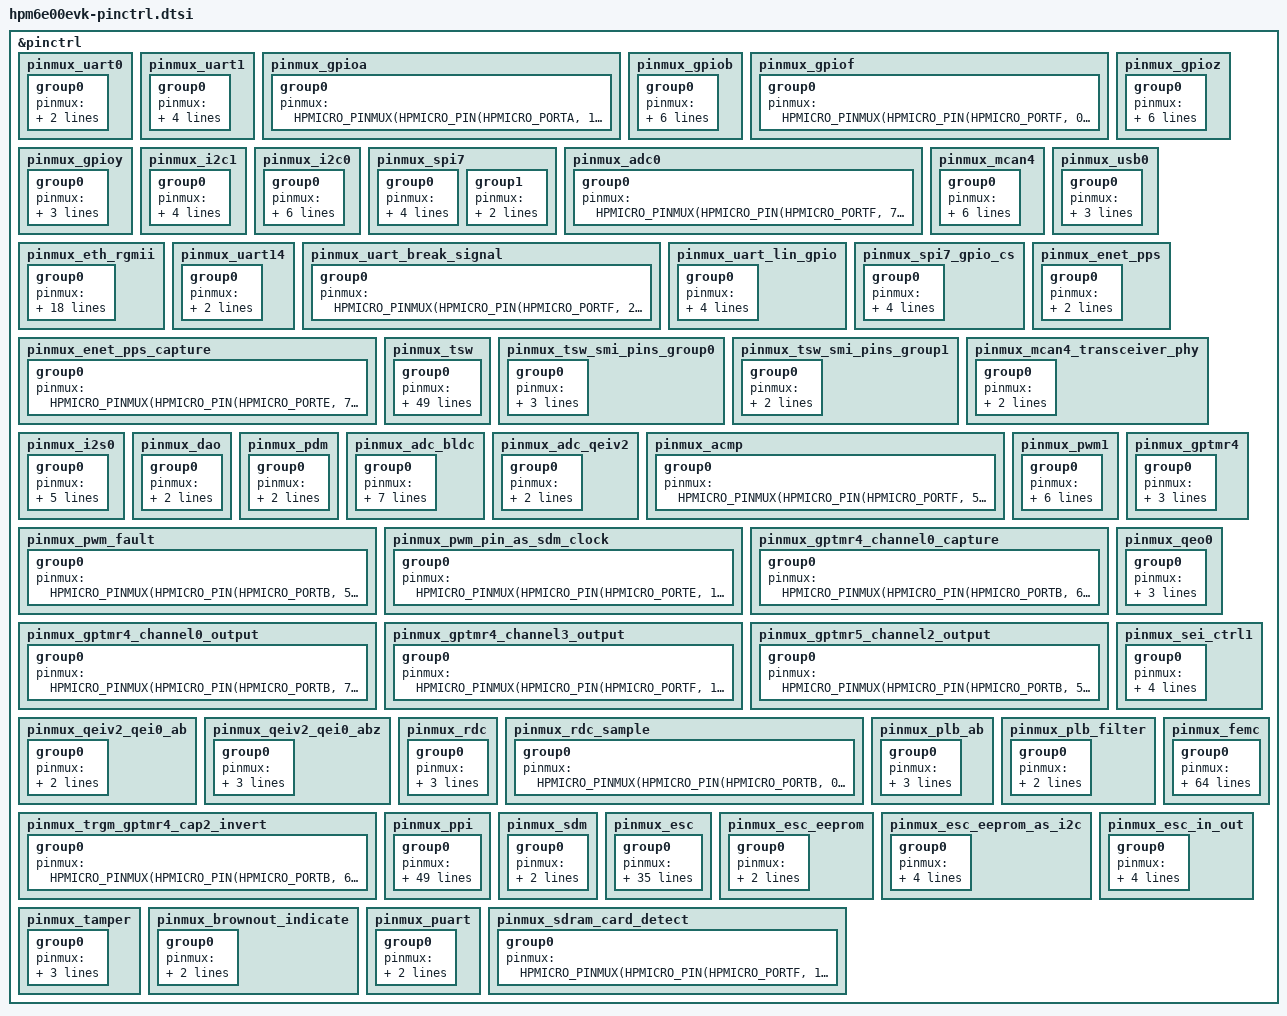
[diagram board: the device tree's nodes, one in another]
/*
* Copyright 2025-2026 HPMicro
* SPDX-License-Identifier: Apache-2.0
*/

#include "dt-bindings/pinctrl/hpmicro-pinctrl-common.h"

&pinctrl {
	pinmux_uart0: pinmux_uart0 {
		group0 {
			pinmux = <HPMICRO_PINMUX(HPMICRO_PIN(HPMICRO_PORTA, 0), IOC_TYPE_IOC, 0, 2)>,
				<HPMICRO_PINMUX(HPMICRO_PIN(HPMICRO_PORTA, 1), IOC_TYPE_IOC, 0, 2)>;
		};
	};

	pinmux_uart1: pinmux_uart1 {
		group0 {
			pinmux = <HPMICRO_PINMUX(HPMICRO_PIN(HPMICRO_PORTY, 7), IOC_TYPE_IOC, 0, 2)>,
				<HPMICRO_PINMUX(HPMICRO_PIN(HPMICRO_PORTY, 7), IOC_TYPE_PIOC, 0, 3)>,
				<HPMICRO_PINMUX(HPMICRO_PIN(HPMICRO_PORTY, 6), IOC_TYPE_IOC, 0, 2)>,
				<HPMICRO_PINMUX(HPMICRO_PIN(HPMICRO_PORTY, 6), IOC_TYPE_PIOC, 0, 3)>;
		};
	};

	pinmux_gpioa: pinmux_gpioa {
		group0 {
			pinmux = <HPMICRO_PINMUX(HPMICRO_PIN(HPMICRO_PORTA, 14), IOC_TYPE_IOC, 0, 0)>;
		};
	};

	pinmux_gpiob: pinmux_gpiob {
		group0 {
			pinmux = <HPMICRO_PINMUX(HPMICRO_PIN(HPMICRO_PORTB, 24), IOC_TYPE_IOC, 0, 0)>,
				<HPMICRO_PINMUX(HPMICRO_PIN(HPMICRO_PORTB, 25), IOC_TYPE_IOC, 0, 0)>;
			bias-pull-up;
			input-enable;
			keeper-capability-disable;
			input-schmitt-enable;
		};
	};

	pinmux_gpiof: pinmux_gpiof {
		group0 {
			pinmux = <HPMICRO_PINMUX(HPMICRO_PIN(HPMICRO_PORTF, 0), IOC_TYPE_IOC, 0, 0)>;
		};
	};

	pinmux_gpioz: pinmux_gpioz {
		group0 {
			pinmux = <HPMICRO_PINMUX(HPMICRO_PIN(HPMICRO_PORTZ, 2), IOC_TYPE_IOC, 0, 0)>,
				<HPMICRO_PINMUX(HPMICRO_PIN(HPMICRO_PORTZ, 2), IOC_TYPE_BIOC, 0, 3)>,
				<HPMICRO_PINMUX(HPMICRO_PIN(HPMICRO_PORTZ, 3), IOC_TYPE_IOC, 0, 0)>,
				<HPMICRO_PINMUX(HPMICRO_PIN(HPMICRO_PORTZ, 3), IOC_TYPE_BIOC, 0, 3)>;
			bias-pull-up;
			input-enable;
		};
	};

	pinmux_gpioy: pinmux_gpioy {
		group0 {
			pinmux = <HPMICRO_PINMUX(HPMICRO_PIN(HPMICRO_PORTY, 5), IOC_TYPE_IOC, 0, 0)>,
				<HPMICRO_PINMUX(HPMICRO_PIN(HPMICRO_PORTY, 5), IOC_TYPE_BIOC, 0, 3)>;
			bias-pull-up;
		};
	};

	pinmux_i2c1: pinmux_i2c1 {
		group0 {
			pinmux = <HPMICRO_PINMUX(HPMICRO_PIN(HPMICRO_PORTF, 12), IOC_TYPE_IOC, 0, 4)>,
				<HPMICRO_PINMUX(HPMICRO_PIN(HPMICRO_PORTF, 13), IOC_TYPE_IOC, 0, 4)>;
			drive-open-drain;
			input-enable;
		};
	};

	pinmux_i2c0: pinmux_i2c0 {
		group0 {
			pinmux = <HPMICRO_PINMUX(HPMICRO_PIN(HPMICRO_PORTY, 2), IOC_TYPE_IOC, 0, 4)>,
				<HPMICRO_PINMUX(HPMICRO_PIN(HPMICRO_PORTY, 2), IOC_TYPE_PIOC, 0, 3)>,
				<HPMICRO_PINMUX(HPMICRO_PIN(HPMICRO_PORTY, 3), IOC_TYPE_IOC, 0, 4)>,
				<HPMICRO_PINMUX(HPMICRO_PIN(HPMICRO_PORTY, 3), IOC_TYPE_PIOC, 0, 3)>;
			drive-open-drain;
			input-enable;
		};
	};

	pinmux_spi7: pinmux_spi7 {
		group0 {
			pinmux = <HPMICRO_PINMUX(HPMICRO_PIN(HPMICRO_PORTF, 26), IOC_TYPE_IOC, 0, 5)>,
				<HPMICRO_PINMUX(HPMICRO_PIN(HPMICRO_PORTF, 28), IOC_TYPE_IOC, 0, 5)>,
				<HPMICRO_PINMUX(HPMICRO_PIN(HPMICRO_PORTF, 29), IOC_TYPE_IOC, 0, 5)>;
			input-enable;
		};

		group1 {
			pinmux = <HPMICRO_PINMUX(HPMICRO_PIN(HPMICRO_PORTF, 27), IOC_TYPE_IOC, 0, 0)>;
			bias-pull-up;
		};
	};

	pinmux_adc0: pinmux_adc0 {
		group0 {
			pinmux = <HPMICRO_PINMUX(HPMICRO_PIN(HPMICRO_PORTF, 7), IOC_TYPE_IOC, 1, 0)>;
		};
	};

	pinmux_mcan4: pinmux_mcan4 {
		group0 {
			pinmux = <HPMICRO_PINMUX(HPMICRO_PIN(HPMICRO_PORTZ, 0), IOC_TYPE_IOC, 0, 7)>,
				<HPMICRO_PINMUX(HPMICRO_PIN(HPMICRO_PORTZ, 1), IOC_TYPE_IOC, 0, 7)>,
				<HPMICRO_PINMUX(HPMICRO_PIN(HPMICRO_PORTZ, 2), IOC_TYPE_IOC, 0, 7)>,
				<HPMICRO_PINMUX(HPMICRO_PIN(HPMICRO_PORTZ, 0), IOC_TYPE_BIOC, 0, 3)>,
				<HPMICRO_PINMUX(HPMICRO_PIN(HPMICRO_PORTZ, 1), IOC_TYPE_BIOC, 0, 3)>,
				<HPMICRO_PINMUX(HPMICRO_PIN(HPMICRO_PORTZ, 2), IOC_TYPE_BIOC, 0, 3)>;
		};
	};

	pinmux_usb0: pinmux_usb0 {
		group0 {
			pinmux = <HPMICRO_PINMUX(HPMICRO_PIN(HPMICRO_PORTF, 19), IOC_TYPE_IOC, 0, 24)>,
				<HPMICRO_PINMUX(HPMICRO_PIN(HPMICRO_PORTF, 22), IOC_TYPE_IOC, 0, 24)>,
				<HPMICRO_PINMUX(HPMICRO_PIN(HPMICRO_PORTF, 23), IOC_TYPE_IOC, 0, 24)>;
		};
	};

	pinmux_eth_rgmii: pinmux_eth_rgmii {
		group0 {
			pinmux = <HPMICRO_PINMUX(HPMICRO_PIN(HPMICRO_PORTF, 1), IOC_TYPE_IOC, 0, 18)>,
				<HPMICRO_PINMUX(HPMICRO_PIN(HPMICRO_PORTF, 0), IOC_TYPE_IOC, 0, 18)>,
				<HPMICRO_PINMUX(HPMICRO_PIN(HPMICRO_PORTE, 20), IOC_TYPE_IOC, 0, 18)>,
				<HPMICRO_PINMUX(HPMICRO_PIN(HPMICRO_PORTE, 21), IOC_TYPE_IOC, 0, 18)>,
				<HPMICRO_PINMUX(HPMICRO_PIN(HPMICRO_PORTE, 22), IOC_TYPE_IOC, 0, 18)>,
				<HPMICRO_PINMUX(HPMICRO_PIN(HPMICRO_PORTE, 23), IOC_TYPE_IOC, 0, 18)>,
				<HPMICRO_PINMUX(HPMICRO_PIN(HPMICRO_PORTE, 24), IOC_TYPE_IOC, 0, 18)>,
				<HPMICRO_PINMUX(HPMICRO_PIN(HPMICRO_PORTE, 25), IOC_TYPE_IOC, 0, 18)>,
				<HPMICRO_PINMUX(HPMICRO_PIN(HPMICRO_PORTE, 26), IOC_TYPE_IOC, 0, 18)>,
				<HPMICRO_PINMUX(HPMICRO_PIN(HPMICRO_PORTE, 27), IOC_TYPE_IOC, 0, 18)>,
				<HPMICRO_PINMUX(HPMICRO_PIN(HPMICRO_PORTE, 28), IOC_TYPE_IOC, 0, 18)>,
				<HPMICRO_PINMUX(HPMICRO_PIN(HPMICRO_PORTE, 29), IOC_TYPE_IOC, 0, 18)>,
				<HPMICRO_PINMUX(HPMICRO_PIN(HPMICRO_PORTE, 30), IOC_TYPE_IOC, 0, 18)>,
				<HPMICRO_PINMUX(HPMICRO_PIN(HPMICRO_PORTE, 31), IOC_TYPE_IOC, 0, 18)>;
			input-schmitt-enable;
			slew-rate = "fast";
			slew-pd = "100M";
			drive-strength = "r011";
		};
	};

	pinmux_uart14: pinmux_uart14 {
		group0 {
			pinmux = <HPMICRO_PINMUX(HPMICRO_PIN(HPMICRO_PORTF, 24), IOC_TYPE_IOC, 0, 2)>,
				<HPMICRO_PINMUX(HPMICRO_PIN(HPMICRO_PORTF, 25), IOC_TYPE_IOC, 0, 2)>;
		};
	};

	pinmux_uart_break_signal: pinmux_uart_break_signal {
		group0 {
			pinmux = <HPMICRO_PINMUX(HPMICRO_PIN(HPMICRO_PORTF, 27), IOC_TYPE_IOC, 0, 0)>;
		};
	};

	pinmux_uart_lin_gpio: pinmux_uart_lin_gpio {
		group0 {
			pinmux = <HPMICRO_PINMUX(HPMICRO_PIN(HPMICRO_PORTY, 7), IOC_TYPE_IOC, 0, 0)>,
				<HPMICRO_PINMUX(HPMICRO_PIN(HPMICRO_PORTY, 7), IOC_TYPE_PIOC, 0, 3)>,
				<HPMICRO_PINMUX(HPMICRO_PIN(HPMICRO_PORTY, 6), IOC_TYPE_IOC, 0, 0)>,
				<HPMICRO_PINMUX(HPMICRO_PIN(HPMICRO_PORTY, 6), IOC_TYPE_PIOC, 0, 3)>;
		};
	};

	pinmux_spi7_gpio_cs: pinmux_spi7_gpio_cs {
		group0 {
			pinmux = <HPMICRO_PINMUX(HPMICRO_PIN(HPMICRO_PORTF, 27), IOC_TYPE_IOC, 0, 0)>,
				<HPMICRO_PINMUX(HPMICRO_PIN(HPMICRO_PORTF, 26), IOC_TYPE_IOC, 0, 5)>,
				<HPMICRO_PINMUX(HPMICRO_PIN(HPMICRO_PORTF, 28), IOC_TYPE_IOC, 0, 5)>,
				<HPMICRO_PINMUX(HPMICRO_PIN(HPMICRO_PORTF, 29), IOC_TYPE_IOC, 0, 5)>;
		};
	};

	pinmux_enet_pps: pinmux_enet_pps {
		group0 {
			pinmux = <HPMICRO_PINMUX(HPMICRO_PIN(HPMICRO_PORTE, 6), IOC_TYPE_IOC, 0, 25)>,
				<HPMICRO_PINMUX(HPMICRO_PIN(HPMICRO_PORTF, 20), IOC_TYPE_IOC, 0, 25)>;
		};
	};

	pinmux_enet_pps_capture: pinmux_enet_pps_capture {
		group0 {
			pinmux = <HPMICRO_PINMUX(HPMICRO_PIN(HPMICRO_PORTE, 7), IOC_TYPE_IOC, 0, 25)>;
		};
	};

	pinmux_tsw: pinmux_tsw {
		group0 {
			pinmux = <HPMICRO_PINMUX(HPMICRO_PIN(HPMICRO_PORTA, 16), IOC_TYPE_IOC, 0, 10)>,
				<HPMICRO_PINMUX(HPMICRO_PIN(HPMICRO_PORTA, 21), IOC_TYPE_IOC, 0, 10)>,
				<HPMICRO_PINMUX(HPMICRO_PIN(HPMICRO_PORTA, 17), IOC_TYPE_IOC, 0, 10)>,
				<HPMICRO_PINMUX(HPMICRO_PIN(HPMICRO_PORTA, 18), IOC_TYPE_IOC, 0, 10)>,
				<HPMICRO_PINMUX(HPMICRO_PIN(HPMICRO_PORTA, 19), IOC_TYPE_IOC, 0, 10)>,
				<HPMICRO_PINMUX(HPMICRO_PIN(HPMICRO_PORTA, 20), IOC_TYPE_IOC, 0, 10)>,
				<HPMICRO_PINMUX(HPMICRO_PIN(HPMICRO_PORTA, 29), IOC_TYPE_IOC, 0, 10)>,
				<HPMICRO_PINMUX(HPMICRO_PIN(HPMICRO_PORTA, 24), IOC_TYPE_IOC, 0, 10)>,
				<HPMICRO_PINMUX(HPMICRO_PIN(HPMICRO_PORTA, 25), IOC_TYPE_IOC, 0, 10)>,
				<HPMICRO_PINMUX(HPMICRO_PIN(HPMICRO_PORTA, 26), IOC_TYPE_IOC, 0, 10)>,
				<HPMICRO_PINMUX(HPMICRO_PIN(HPMICRO_PORTA, 27), IOC_TYPE_IOC, 0, 10)>,
				<HPMICRO_PINMUX(HPMICRO_PIN(HPMICRO_PORTA, 28), IOC_TYPE_IOC, 0, 10)>,
				<HPMICRO_PINMUX(HPMICRO_PIN(HPMICRO_PORTA, 23), IOC_TYPE_IOC, 0, 10)>,
				<HPMICRO_PINMUX(HPMICRO_PIN(HPMICRO_PORTA, 30), IOC_TYPE_IOC, 0, 10)>,
				<HPMICRO_PINMUX(HPMICRO_PIN(HPMICRO_PORTA, 31), IOC_TYPE_IOC, 0, 10)>,
				<HPMICRO_PINMUX(HPMICRO_PIN(HPMICRO_PORTB, 12), IOC_TYPE_IOC, 0, 10)>,
				<HPMICRO_PINMUX(HPMICRO_PIN(HPMICRO_PORTB, 17), IOC_TYPE_IOC, 0, 10)>,
				<HPMICRO_PINMUX(HPMICRO_PIN(HPMICRO_PORTB, 13), IOC_TYPE_IOC, 0, 10)>,
				<HPMICRO_PINMUX(HPMICRO_PIN(HPMICRO_PORTB, 14), IOC_TYPE_IOC, 0, 10)>,
				<HPMICRO_PINMUX(HPMICRO_PIN(HPMICRO_PORTB, 15), IOC_TYPE_IOC, 0, 10)>,
				<HPMICRO_PINMUX(HPMICRO_PIN(HPMICRO_PORTB, 16), IOC_TYPE_IOC, 0, 10)>,
				<HPMICRO_PINMUX(HPMICRO_PIN(HPMICRO_PORTB, 23), IOC_TYPE_IOC, 0, 10)>,
				<HPMICRO_PINMUX(HPMICRO_PIN(HPMICRO_PORTB, 18), IOC_TYPE_IOC, 0, 10)>,
				<HPMICRO_PINMUX(HPMICRO_PIN(HPMICRO_PORTB, 19), IOC_TYPE_IOC, 0, 10)>,
				<HPMICRO_PINMUX(HPMICRO_PIN(HPMICRO_PORTB, 20), IOC_TYPE_IOC, 0, 10)>,
				<HPMICRO_PINMUX(HPMICRO_PIN(HPMICRO_PORTB, 21), IOC_TYPE_IOC, 0, 10)>,
				<HPMICRO_PINMUX(HPMICRO_PIN(HPMICRO_PORTB, 22), IOC_TYPE_IOC, 0, 10)>,
				<HPMICRO_PINMUX(HPMICRO_PIN(HPMICRO_PORTA, 22), IOC_TYPE_IOC, 0, 10)>,
				<HPMICRO_PINMUX(HPMICRO_PIN(HPMICRO_PORTE, 3), IOC_TYPE_IOC, 0, 10)>,
				<HPMICRO_PINMUX(HPMICRO_PIN(HPMICRO_PORTE, 4), IOC_TYPE_IOC, 0, 10)>,
				<HPMICRO_PINMUX(HPMICRO_PIN(HPMICRO_PORTA, 10), IOC_TYPE_IOC, 0, 0)>,
				<HPMICRO_PINMUX(HPMICRO_PIN(HPMICRO_PORTA, 9), IOC_TYPE_IOC, 0, 11)>,
				<HPMICRO_PINMUX(HPMICRO_PIN(HPMICRO_PORTE, 20), IOC_TYPE_IOC, 0, 10)>,
				<HPMICRO_PINMUX(HPMICRO_PIN(HPMICRO_PORTE, 25), IOC_TYPE_IOC, 0, 10)>,
				<HPMICRO_PINMUX(HPMICRO_PIN(HPMICRO_PORTE, 21), IOC_TYPE_IOC, 0, 10)>,
				<HPMICRO_PINMUX(HPMICRO_PIN(HPMICRO_PORTE, 22), IOC_TYPE_IOC, 0, 10)>,
				<HPMICRO_PINMUX(HPMICRO_PIN(HPMICRO_PORTE, 23), IOC_TYPE_IOC, 0, 10)>,
				<HPMICRO_PINMUX(HPMICRO_PIN(HPMICRO_PORTE, 24), IOC_TYPE_IOC, 0, 10)>,
				<HPMICRO_PINMUX(HPMICRO_PIN(HPMICRO_PORTE, 31), IOC_TYPE_IOC, 0, 10)>,
				<HPMICRO_PINMUX(HPMICRO_PIN(HPMICRO_PORTE, 26), IOC_TYPE_IOC, 0, 10)>,
				<HPMICRO_PINMUX(HPMICRO_PIN(HPMICRO_PORTE, 27), IOC_TYPE_IOC, 0, 10)>,
				<HPMICRO_PINMUX(HPMICRO_PIN(HPMICRO_PORTE, 28), IOC_TYPE_IOC, 0, 10)>,
				<HPMICRO_PINMUX(HPMICRO_PIN(HPMICRO_PORTE, 29), IOC_TYPE_IOC, 0, 10)>,
				<HPMICRO_PINMUX(HPMICRO_PIN(HPMICRO_PORTE, 30), IOC_TYPE_IOC, 0, 10)>,
				<HPMICRO_PINMUX(HPMICRO_PIN(HPMICRO_PORTF, 0), IOC_TYPE_IOC, 0, 10)>,
				<HPMICRO_PINMUX(HPMICRO_PIN(HPMICRO_PORTF, 1), IOC_TYPE_IOC, 0, 10)>,
				<HPMICRO_PINMUX(HPMICRO_PIN(HPMICRO_PORTB, 9), IOC_TYPE_IOC, 0, 0)>,
				<HPMICRO_PINMUX(HPMICRO_PIN(HPMICRO_PORTA, 14), IOC_TYPE_IOC, 0, 0)>,
				<HPMICRO_PINMUX(HPMICRO_PIN(HPMICRO_PORTB, 25), IOC_TYPE_IOC, 0, 26)>;
		};
	};

	pinmux_tsw_smi_pins_group0: pinmux_tsw_smi_pins_group0 {
		group0 {
			pinmux = <HPMICRO_PINMUX(HPMICRO_PIN(HPMICRO_PORTA, 30), IOC_TYPE_IOC, 0, 18)>,
				<HPMICRO_PINMUX(HPMICRO_PIN(HPMICRO_PORTA, 31), IOC_TYPE_IOC, 0, 18)>,
				<HPMICRO_PINMUX(HPMICRO_PIN(HPMICRO_PORTA, 9), IOC_TYPE_IOC, 0, 11)>;
		};
	};

	pinmux_tsw_smi_pins_group1: pinmux_tsw_smi_pins_group1 {
		group0 {
			pinmux = <HPMICRO_PINMUX(HPMICRO_PIN(HPMICRO_PORTF, 1), IOC_TYPE_IOC, 0, 18)>,
				<HPMICRO_PINMUX(HPMICRO_PIN(HPMICRO_PORTF, 0), IOC_TYPE_IOC, 0, 18)>;
		};
	};

	pinmux_mcan4_transceiver_phy: pinmux_mcan4_transceiver_phy {
		group0 {
			pinmux = <HPMICRO_PINMUX(HPMICRO_PIN(HPMICRO_PORTZ, 2), IOC_TYPE_IOC, 0, 0)>,
				<HPMICRO_PINMUX(HPMICRO_PIN(HPMICRO_PORTZ, 2), IOC_TYPE_BIOC, 0, 3)>;
		};
	};

	pinmux_i2s0: pinmux_i2s0 {
		group0 {
			pinmux = <HPMICRO_PINMUX(HPMICRO_PIN(HPMICRO_PORTB, 11), IOC_TYPE_IOC, 0, 8)>,
				<HPMICRO_PINMUX(HPMICRO_PIN(HPMICRO_PORTB, 1), IOC_TYPE_IOC, 0, 8)>,
				<HPMICRO_PINMUX(HPMICRO_PIN(HPMICRO_PORTB, 10), IOC_TYPE_IOC, 0, 8)>,
				<HPMICRO_PINMUX(HPMICRO_PIN(HPMICRO_PORTB, 0), IOC_TYPE_IOC, 0, 8)>,
				<HPMICRO_PINMUX(HPMICRO_PIN(HPMICRO_PORTB, 8), IOC_TYPE_IOC, 0, 8)>;
		};
	};

	pinmux_dao: pinmux_dao {
		group0 {
			pinmux = <HPMICRO_PINMUX(HPMICRO_PIN(HPMICRO_PORTF, 4), IOC_TYPE_IOC, 0, 9)>,
				<HPMICRO_PINMUX(HPMICRO_PIN(HPMICRO_PORTF, 3), IOC_TYPE_IOC, 0, 9)>;
		};
	};

	pinmux_pdm: pinmux_pdm {
		group0 {
			pinmux = <HPMICRO_PINMUX(HPMICRO_PIN(HPMICRO_PORTB, 2), IOC_TYPE_IOC, 0, 9)>,
				<HPMICRO_PINMUX(HPMICRO_PIN(HPMICRO_PORTB, 3), IOC_TYPE_IOC, 0, 9)>;
		};
	};

	pinmux_adc_bldc: pinmux_adc_bldc {
		group0 {
			pinmux = <HPMICRO_PINMUX(HPMICRO_PIN(HPMICRO_PORTF, 6), IOC_TYPE_IOC, 1, 0)>,
				<HPMICRO_PINMUX(HPMICRO_PIN(HPMICRO_PORTF, 8), IOC_TYPE_IOC, 1, 0)>,
				<HPMICRO_PINMUX(HPMICRO_PIN(HPMICRO_PORTF, 19), IOC_TYPE_IOC, 1, 0)>,
				<HPMICRO_PINMUX(HPMICRO_PIN(HPMICRO_PORTF, 10), IOC_TYPE_IOC, 1, 0)>,
				<HPMICRO_PINMUX(HPMICRO_PIN(HPMICRO_PORTF, 7), IOC_TYPE_IOC, 1, 0)>,
				<HPMICRO_PINMUX(HPMICRO_PIN(HPMICRO_PORTF, 27), IOC_TYPE_IOC, 1, 0)>,
				<HPMICRO_PINMUX(HPMICRO_PIN(HPMICRO_PORTF, 20), IOC_TYPE_IOC, 1, 0)>;
		};
	};

	pinmux_adc_qeiv2: pinmux_adc_qeiv2 {
		group0 {
			pinmux = <HPMICRO_PINMUX(HPMICRO_PIN(HPMICRO_PORTF, 19), IOC_TYPE_IOC, 1, 0)>,
				<HPMICRO_PINMUX(HPMICRO_PIN(HPMICRO_PORTF, 6), IOC_TYPE_IOC, 1, 0)>;
		};
	};

	pinmux_acmp: pinmux_acmp {
		group0 {
			pinmux = <HPMICRO_PINMUX(HPMICRO_PIN(HPMICRO_PORTF, 5), IOC_TYPE_IOC, 1, 0)>;
		};
	};

	pinmux_pwm1: pinmux_pwm1 {
		group0 {
			pinmux = <HPMICRO_PINMUX(HPMICRO_PIN(HPMICRO_PORTE, 8), IOC_TYPE_IOC, 0, 16)>,
				<HPMICRO_PINMUX(HPMICRO_PIN(HPMICRO_PORTE, 9), IOC_TYPE_IOC, 0, 16)>,
				<HPMICRO_PINMUX(HPMICRO_PIN(HPMICRO_PORTE, 10), IOC_TYPE_IOC, 0, 16)>,
				<HPMICRO_PINMUX(HPMICRO_PIN(HPMICRO_PORTE, 11), IOC_TYPE_IOC, 0, 16)>,
				<HPMICRO_PINMUX(HPMICRO_PIN(HPMICRO_PORTE, 12), IOC_TYPE_IOC, 0, 16)>,
				<HPMICRO_PINMUX(HPMICRO_PIN(HPMICRO_PORTE, 13), IOC_TYPE_IOC, 0, 16)>;
		};
	};

	pinmux_pwm_fault: pinmux_pwm_fault {
		group0 {
			pinmux = <HPMICRO_PINMUX(HPMICRO_PIN(HPMICRO_PORTB, 5), IOC_TYPE_IOC, 0, 17)>;
		};
	};

	pinmux_pwm_pin_as_sdm_clock: pinmux_pwm_pin_as_sdm_clock {
		group0 {
			pinmux = <HPMICRO_PINMUX(HPMICRO_PIN(HPMICRO_PORTE, 19), IOC_TYPE_IOC, 0, 16)>;
		};
	};

	pinmux_gptmr4: pinmux_gptmr4 {
		group0 {
			pinmux = <HPMICRO_PINMUX(HPMICRO_PIN(HPMICRO_PORTB, 6), IOC_TYPE_IOC, 0, 1)>,
				<HPMICRO_PINMUX(HPMICRO_PIN(HPMICRO_PORTB, 7), IOC_TYPE_IOC, 0, 1)>,
				<HPMICRO_PINMUX(HPMICRO_PIN(HPMICRO_PORTF, 15), IOC_TYPE_IOC, 0, 1)>;
		};
	};

	pinmux_gptmr4_channel0_capture: pinmux_gptmr4_channel0_capture {
		group0 {
			pinmux = <HPMICRO_PINMUX(HPMICRO_PIN(HPMICRO_PORTB, 6), IOC_TYPE_IOC, 0, 1)>;
		};
	};

	pinmux_gptmr4_channel0_output: pinmux_gptmr4_channel0_output {
		group0 {
			pinmux = <HPMICRO_PINMUX(HPMICRO_PIN(HPMICRO_PORTB, 7), IOC_TYPE_IOC, 0, 1)>;
		};
	};

	pinmux_gptmr4_channel3_output: pinmux_gptmr4_channel3_output {
		group0 {
			pinmux = <HPMICRO_PINMUX(HPMICRO_PIN(HPMICRO_PORTF, 15), IOC_TYPE_IOC, 0, 1)>;
		};
	};

	pinmux_gptmr5_channel2_output: pinmux_gptmr5_channel2_output {
		group0 {
			pinmux = <HPMICRO_PINMUX(HPMICRO_PIN(HPMICRO_PORTB, 5), IOC_TYPE_IOC, 0, 1)>;
		};
	};

	pinmux_qeo0: pinmux_qeo0 {
		group0 {
			pinmux = <HPMICRO_PINMUX(HPMICRO_PIN(HPMICRO_PORTE, 7), IOC_TYPE_IOC, 0, 21)>,
				<HPMICRO_PINMUX(HPMICRO_PIN(HPMICRO_PORTE, 6), IOC_TYPE_IOC, 0, 21)>,
				<HPMICRO_PINMUX(HPMICRO_PIN(HPMICRO_PORTE, 5), IOC_TYPE_IOC, 0, 21)>;
		};
	};

	pinmux_qeiv2_qei0_ab: pinmux_qeiv2_qei0_ab {
		group0 {
			pinmux = <HPMICRO_PINMUX(HPMICRO_PIN(HPMICRO_PORTB, 7), IOC_TYPE_IOC, 0, 20)>,
				<HPMICRO_PINMUX(HPMICRO_PIN(HPMICRO_PORTB, 6), IOC_TYPE_IOC, 0, 20)>;
		};
	};

	pinmux_qeiv2_qei0_abz: pinmux_qeiv2_qei0_abz {
		group0 {
			pinmux = <HPMICRO_PINMUX(HPMICRO_PIN(HPMICRO_PORTB, 7), IOC_TYPE_IOC, 0, 20)>,
				<HPMICRO_PINMUX(HPMICRO_PIN(HPMICRO_PORTB, 6), IOC_TYPE_IOC, 0, 20)>,
				<HPMICRO_PINMUX(HPMICRO_PIN(HPMICRO_PORTB, 5), IOC_TYPE_IOC, 0, 20)>;
		};
	};

	pinmux_sei_ctrl1: pinmux_sei_ctrl1 {
		group0 {
			pinmux = <HPMICRO_PINMUX(HPMICRO_PIN(HPMICRO_PORTE, 18), IOC_TYPE_IOC, 0, 22)>,
				<HPMICRO_PINMUX(HPMICRO_PIN(HPMICRO_PORTE, 19), IOC_TYPE_IOC, 0, 22)>,
				<HPMICRO_PINMUX(HPMICRO_PIN(HPMICRO_PORTE, 16), IOC_TYPE_IOC, 0, 22)>,
				<HPMICRO_PINMUX(HPMICRO_PIN(HPMICRO_PORTE, 17), IOC_TYPE_IOC, 0, 22)>;
		};
	};

	pinmux_rdc: pinmux_rdc {
		group0 {
			pinmux = <HPMICRO_PINMUX(HPMICRO_PIN(HPMICRO_PORTF, 6), IOC_TYPE_IOC, 1, 0)>,
				<HPMICRO_PINMUX(HPMICRO_PIN(HPMICRO_PORTF, 8), IOC_TYPE_IOC, 1, 0)>,
				<HPMICRO_PINMUX(HPMICRO_PIN(HPMICRO_PORTE, 8), IOC_TYPE_IOC, 0, 20)>;
		};
	};

	pinmux_rdc_sample: pinmux_rdc_sample {
		group0 {
			pinmux = <HPMICRO_PINMUX(HPMICRO_PIN(HPMICRO_PORTB, 0), IOC_TYPE_IOC, 0, 17)>;
		};
	};

	pinmux_plb_ab: pinmux_plb_ab {
		group0 {
			pinmux = <HPMICRO_PINMUX(HPMICRO_PIN(HPMICRO_PORTB, 7), IOC_TYPE_IOC, 0, 17)>,
				<HPMICRO_PINMUX(HPMICRO_PIN(HPMICRO_PORTB, 6), IOC_TYPE_IOC, 0, 17)>,
				<HPMICRO_PINMUX(HPMICRO_PIN(HPMICRO_PORTB, 5), IOC_TYPE_IOC, 0, 17)>;
		};
	};

	pinmux_plb_filter: pinmux_plb_filter {
		group0 {
			pinmux = <HPMICRO_PINMUX(HPMICRO_PIN(HPMICRO_PORTE, 10), IOC_TYPE_IOC, 0, 17)>,
				<HPMICRO_PINMUX(HPMICRO_PIN(HPMICRO_PORTE, 12), IOC_TYPE_IOC, 0, 17)>;
		};
	};

	pinmux_trgm_gptmr4_cap2_invert: pinmux_trgm_gptmr4_cap2_invert {
		group0 {
			pinmux = <HPMICRO_PINMUX(HPMICRO_PIN(HPMICRO_PORTB, 6), IOC_TYPE_IOC, 0, 17)>;
		};
	};

	pinmux_femc: pinmux_femc {
		group0 {
			pinmux = <HPMICRO_PINMUX(HPMICRO_PIN(HPMICRO_PORTD, 2), IOC_TYPE_IOC, 0, 12)>,
				<HPMICRO_PINMUX(HPMICRO_PIN(HPMICRO_PORTD, 3), IOC_TYPE_IOC, 0, 12)>,
				<HPMICRO_PINMUX(HPMICRO_PIN(HPMICRO_PORTD, 0), IOC_TYPE_IOC, 0, 12)>,
				<HPMICRO_PINMUX(HPMICRO_PIN(HPMICRO_PORTD, 1), IOC_TYPE_IOC, 0, 12)>,
				<HPMICRO_PINMUX(HPMICRO_PIN(HPMICRO_PORTC, 18), IOC_TYPE_IOC, 0, 12)>,
				<HPMICRO_PINMUX(HPMICRO_PIN(HPMICRO_PORTC, 19), IOC_TYPE_IOC, 0, 12)>,
				<HPMICRO_PINMUX(HPMICRO_PIN(HPMICRO_PORTC, 20), IOC_TYPE_IOC, 0, 12)>,
				<HPMICRO_PINMUX(HPMICRO_PIN(HPMICRO_PORTC, 21), IOC_TYPE_IOC, 0, 12)>,
				<HPMICRO_PINMUX(HPMICRO_PIN(HPMICRO_PORTC, 23), IOC_TYPE_IOC, 0, 12)>,
				<HPMICRO_PINMUX(HPMICRO_PIN(HPMICRO_PORTC, 24), IOC_TYPE_IOC, 0, 12)>,
				<HPMICRO_PINMUX(HPMICRO_PIN(HPMICRO_PORTD, 4), IOC_TYPE_IOC, 0, 12)>,
				<HPMICRO_PINMUX(HPMICRO_PIN(HPMICRO_PORTC, 25), IOC_TYPE_IOC, 0, 12)>,
				<HPMICRO_PINMUX(HPMICRO_PIN(HPMICRO_PORTC, 26), IOC_TYPE_IOC, 0, 12)>,
				<HPMICRO_PINMUX(HPMICRO_PIN(HPMICRO_PORTD, 31), IOC_TYPE_IOC, 0, 12)>,
				<HPMICRO_PINMUX(HPMICRO_PIN(HPMICRO_PORTD, 30), IOC_TYPE_IOC, 0, 12)>,
				<HPMICRO_PINMUX(HPMICRO_PIN(HPMICRO_PORTD, 29), IOC_TYPE_IOC, 0, 12)>,
				<HPMICRO_PINMUX(HPMICRO_PIN(HPMICRO_PORTD, 28), IOC_TYPE_IOC, 0, 12)>,
				<HPMICRO_PINMUX(HPMICRO_PIN(HPMICRO_PORTD, 27), IOC_TYPE_IOC, 0, 12)>,
				<HPMICRO_PINMUX(HPMICRO_PIN(HPMICRO_PORTD, 26), IOC_TYPE_IOC, 0, 12)>,
				<HPMICRO_PINMUX(HPMICRO_PIN(HPMICRO_PORTD, 24), IOC_TYPE_IOC, 0, 12)>,
				<HPMICRO_PINMUX(HPMICRO_PIN(HPMICRO_PORTD, 25), IOC_TYPE_IOC, 0, 12)>,
				<HPMICRO_PINMUX(HPMICRO_PIN(HPMICRO_PORTD, 14), IOC_TYPE_IOC, 0, 12)>,
				<HPMICRO_PINMUX(HPMICRO_PIN(HPMICRO_PORTD, 17), IOC_TYPE_IOC, 0, 12)>,
				<HPMICRO_PINMUX(HPMICRO_PIN(HPMICRO_PORTD, 16), IOC_TYPE_IOC, 0, 12)>,
				<HPMICRO_PINMUX(HPMICRO_PIN(HPMICRO_PORTD, 19), IOC_TYPE_IOC, 0, 12)>,
				<HPMICRO_PINMUX(HPMICRO_PIN(HPMICRO_PORTD, 18), IOC_TYPE_IOC, 0, 12)>,
				<HPMICRO_PINMUX(HPMICRO_PIN(HPMICRO_PORTD, 21), IOC_TYPE_IOC, 0, 12)>,
				<HPMICRO_PINMUX(HPMICRO_PIN(HPMICRO_PORTD, 20), IOC_TYPE_IOC, 0, 12)>,
				<HPMICRO_PINMUX(HPMICRO_PIN(HPMICRO_PORTD, 22), IOC_TYPE_IOC, 0, 12)>,
				<HPMICRO_PINMUX(HPMICRO_PIN(HPMICRO_PORTC, 16), IOC_TYPE_IOC, 0, 12)>,
				<HPMICRO_PINMUX(HPMICRO_PIN(HPMICRO_PORTC, 17), IOC_TYPE_IOC, 0, 12)>,
				<HPMICRO_PINMUX(HPMICRO_PIN(HPMICRO_PORTC, 13), IOC_TYPE_IOC, 0, 12)>,
				<HPMICRO_PINMUX(HPMICRO_PIN(HPMICRO_PORTC, 14), IOC_TYPE_IOC, 0, 12)>,
				<HPMICRO_PINMUX(HPMICRO_PIN(HPMICRO_PORTC, 10), IOC_TYPE_IOC, 0, 12)>,
				<HPMICRO_PINMUX(HPMICRO_PIN(HPMICRO_PORTC, 11), IOC_TYPE_IOC, 0, 12)>,
				<HPMICRO_PINMUX(HPMICRO_PIN(HPMICRO_PORTC, 2), IOC_TYPE_IOC, 0, 12)>,
				<HPMICRO_PINMUX(HPMICRO_PIN(HPMICRO_PORTC, 9), IOC_TYPE_IOC, 0, 12)>,
				<HPMICRO_PINMUX(HPMICRO_PIN(HPMICRO_PORTC, 0), IOC_TYPE_IOC, 0, 12)>,
				<HPMICRO_PINMUX(HPMICRO_PIN(HPMICRO_PORTC, 1), IOC_TYPE_IOC, 0, 12)>,
				<HPMICRO_PINMUX(HPMICRO_PIN(HPMICRO_PORTC, 3), IOC_TYPE_IOC, 0, 12)>,
				<HPMICRO_PINMUX(HPMICRO_PIN(HPMICRO_PORTC, 4), IOC_TYPE_IOC, 0, 12)>,
				<HPMICRO_PINMUX(HPMICRO_PIN(HPMICRO_PORTC, 5), IOC_TYPE_IOC, 0, 12)>,
				<HPMICRO_PINMUX(HPMICRO_PIN(HPMICRO_PORTC, 6), IOC_TYPE_IOC, 0, 12)>,
				<HPMICRO_PINMUX(HPMICRO_PIN(HPMICRO_PORTC, 7), IOC_TYPE_IOC, 0, 12)>,
				<HPMICRO_PINMUX(HPMICRO_PIN(HPMICRO_PORTC, 8), IOC_TYPE_IOC, 0, 12)>,
				<HPMICRO_PINMUX(HPMICRO_PIN(HPMICRO_PORTD, 23), IOC_TYPE_IOC, 0, 12)>,
				<HPMICRO_PINMUX(HPMICRO_PIN(HPMICRO_PORTD, 15), IOC_TYPE_IOC, 0, 12)>,
				<HPMICRO_PINMUX(HPMICRO_PIN(HPMICRO_PORTC, 12), IOC_TYPE_IOC, 0, 12)>,
				<HPMICRO_PINMUX(HPMICRO_PIN(HPMICRO_PORTC, 15), IOC_TYPE_IOC, 0, 12)>,
				<HPMICRO_PINMUX(HPMICRO_PIN(HPMICRO_PORTD, 5), IOC_TYPE_IOC, 0, 12)>,
				<HPMICRO_PINMUX(HPMICRO_PIN(HPMICRO_PORTD, 6), IOC_TYPE_IOC, 0, 12)>,
				<HPMICRO_PINMUX(HPMICRO_PIN(HPMICRO_PORTD, 10), IOC_TYPE_IOC, 0, 12)>,
				<HPMICRO_PINMUX(HPMICRO_PIN(HPMICRO_PORTD, 13), IOC_TYPE_IOC, 0, 12)>,
				<HPMICRO_PINMUX(HPMICRO_PIN(HPMICRO_PORTC, 28), IOC_TYPE_IOC, 0, 12)>,
				<HPMICRO_PINMUX(HPMICRO_PIN(HPMICRO_PORTC, 27), IOC_TYPE_IOC, 0, 12)>,
				<HPMICRO_PINMUX(HPMICRO_PIN(HPMICRO_PORTD, 12), IOC_TYPE_IOC, 0, 12)>,
				<HPMICRO_PINMUX(HPMICRO_PIN(HPMICRO_PORTD, 11), IOC_TYPE_IOC, 0, 12)>,
				<HPMICRO_PINMUX(HPMICRO_PIN(HPMICRO_PORTD, 8), IOC_TYPE_IOC, 0, 12)>,
				<HPMICRO_PINMUX(HPMICRO_PIN(HPMICRO_PORTC, 29), IOC_TYPE_IOC, 0, 12)>,
				<HPMICRO_PINMUX(HPMICRO_PIN(HPMICRO_PORTD, 7), IOC_TYPE_IOC, 0, 12)>,
				<HPMICRO_PINMUX(HPMICRO_PIN(HPMICRO_PORTC, 30), IOC_TYPE_IOC, 0, 12)>,
				<HPMICRO_PINMUX(HPMICRO_PIN(HPMICRO_PORTC, 31), IOC_TYPE_IOC, 0, 12)>,
				<HPMICRO_PINMUX(HPMICRO_PIN(HPMICRO_PORTC, 22), IOC_TYPE_IOC, 0, 12)>,
				<HPMICRO_PINMUX(HPMICRO_PIN(HPMICRO_PORTX, 7), IOC_TYPE_IOC, 0, 12)>;
		};
	};

	pinmux_ppi: pinmux_ppi {
		group0 {
			pinmux = <HPMICRO_PINMUX(HPMICRO_PIN(HPMICRO_PORTD, 31), IOC_TYPE_IOC, 0, 13)>,
				<HPMICRO_PINMUX(HPMICRO_PIN(HPMICRO_PORTD, 30), IOC_TYPE_IOC, 0, 13)>,
				<HPMICRO_PINMUX(HPMICRO_PIN(HPMICRO_PORTD, 29), IOC_TYPE_IOC, 0, 13)>,
				<HPMICRO_PINMUX(HPMICRO_PIN(HPMICRO_PORTD, 28), IOC_TYPE_IOC, 0, 13)>,
				<HPMICRO_PINMUX(HPMICRO_PIN(HPMICRO_PORTD, 27), IOC_TYPE_IOC, 0, 13)>,
				<HPMICRO_PINMUX(HPMICRO_PIN(HPMICRO_PORTD, 26), IOC_TYPE_IOC, 0, 13)>,
				<HPMICRO_PINMUX(HPMICRO_PIN(HPMICRO_PORTD, 24), IOC_TYPE_IOC, 0, 13)>,
				<HPMICRO_PINMUX(HPMICRO_PIN(HPMICRO_PORTD, 25), IOC_TYPE_IOC, 0, 13)>,
				<HPMICRO_PINMUX(HPMICRO_PIN(HPMICRO_PORTD, 14), IOC_TYPE_IOC, 0, 13)>,
				<HPMICRO_PINMUX(HPMICRO_PIN(HPMICRO_PORTD, 17), IOC_TYPE_IOC, 0, 13)>,
				<HPMICRO_PINMUX(HPMICRO_PIN(HPMICRO_PORTD, 16), IOC_TYPE_IOC, 0, 13)>,
				<HPMICRO_PINMUX(HPMICRO_PIN(HPMICRO_PORTD, 19), IOC_TYPE_IOC, 0, 13)>,
				<HPMICRO_PINMUX(HPMICRO_PIN(HPMICRO_PORTD, 18), IOC_TYPE_IOC, 0, 13)>,
				<HPMICRO_PINMUX(HPMICRO_PIN(HPMICRO_PORTD, 21), IOC_TYPE_IOC, 0, 13)>,
				<HPMICRO_PINMUX(HPMICRO_PIN(HPMICRO_PORTD, 20), IOC_TYPE_IOC, 0, 13)>,
				<HPMICRO_PINMUX(HPMICRO_PIN(HPMICRO_PORTD, 22), IOC_TYPE_IOC, 0, 13)>,
				<HPMICRO_PINMUX(HPMICRO_PIN(HPMICRO_PORTC, 16), IOC_TYPE_IOC, 0, 13)>,
				<HPMICRO_PINMUX(HPMICRO_PIN(HPMICRO_PORTC, 17), IOC_TYPE_IOC, 0, 13)>,
				<HPMICRO_PINMUX(HPMICRO_PIN(HPMICRO_PORTC, 13), IOC_TYPE_IOC, 0, 13)>,
				<HPMICRO_PINMUX(HPMICRO_PIN(HPMICRO_PORTC, 14), IOC_TYPE_IOC, 0, 13)>,
				<HPMICRO_PINMUX(HPMICRO_PIN(HPMICRO_PORTC, 10), IOC_TYPE_IOC, 0, 13)>,
				<HPMICRO_PINMUX(HPMICRO_PIN(HPMICRO_PORTC, 11), IOC_TYPE_IOC, 0, 13)>,
				<HPMICRO_PINMUX(HPMICRO_PIN(HPMICRO_PORTC, 2), IOC_TYPE_IOC, 0, 13)>,
				<HPMICRO_PINMUX(HPMICRO_PIN(HPMICRO_PORTC, 9), IOC_TYPE_IOC, 0, 13)>,
				<HPMICRO_PINMUX(HPMICRO_PIN(HPMICRO_PORTC, 0), IOC_TYPE_IOC, 0, 13)>,
				<HPMICRO_PINMUX(HPMICRO_PIN(HPMICRO_PORTC, 1), IOC_TYPE_IOC, 0, 13)>,
				<HPMICRO_PINMUX(HPMICRO_PIN(HPMICRO_PORTC, 3), IOC_TYPE_IOC, 0, 13)>,
				<HPMICRO_PINMUX(HPMICRO_PIN(HPMICRO_PORTC, 4), IOC_TYPE_IOC, 0, 13)>,
				<HPMICRO_PINMUX(HPMICRO_PIN(HPMICRO_PORTC, 5), IOC_TYPE_IOC, 0, 13)>,
				<HPMICRO_PINMUX(HPMICRO_PIN(HPMICRO_PORTC, 6), IOC_TYPE_IOC, 0, 13)>,
				<HPMICRO_PINMUX(HPMICRO_PIN(HPMICRO_PORTC, 7), IOC_TYPE_IOC, 0, 13)>,
				<HPMICRO_PINMUX(HPMICRO_PIN(HPMICRO_PORTC, 8), IOC_TYPE_IOC, 0, 13)>,
				<HPMICRO_PINMUX(HPMICRO_PIN(HPMICRO_PORTD, 23), IOC_TYPE_IOC, 0, 13)>,
				<HPMICRO_PINMUX(HPMICRO_PIN(HPMICRO_PORTD, 15), IOC_TYPE_IOC, 0, 13)>,
				<HPMICRO_PINMUX(HPMICRO_PIN(HPMICRO_PORTC, 12), IOC_TYPE_IOC, 0, 13)>,
				<HPMICRO_PINMUX(HPMICRO_PIN(HPMICRO_PORTC, 15), IOC_TYPE_IOC, 0, 13)>,
				<HPMICRO_PINMUX(HPMICRO_PIN(HPMICRO_PORTC, 30), IOC_TYPE_IOC, 0, 13)>,
				<HPMICRO_PINMUX(HPMICRO_PIN(HPMICRO_PORTC, 31), IOC_TYPE_IOC, 0, 13)>,
				<HPMICRO_PINMUX(HPMICRO_PIN(HPMICRO_PORTD, 11), IOC_TYPE_IOC, 0, 13)>,
				<HPMICRO_PINMUX(HPMICRO_PIN(HPMICRO_PORTD, 8), IOC_TYPE_IOC, 0, 13)>,
				<HPMICRO_PINMUX(HPMICRO_PIN(HPMICRO_PORTC, 27), IOC_TYPE_IOC, 0, 13)>,
				<HPMICRO_PINMUX(HPMICRO_PIN(HPMICRO_PORTD, 10), IOC_TYPE_IOC, 0, 13)>,
				<HPMICRO_PINMUX(HPMICRO_PIN(HPMICRO_PORTC, 22), IOC_TYPE_IOC, 0, 13)>,
				<HPMICRO_PINMUX(HPMICRO_PIN(HPMICRO_PORTD, 7), IOC_TYPE_IOC, 0, 13)>,
				<HPMICRO_PINMUX(HPMICRO_PIN(HPMICRO_PORTE, 0), IOC_TYPE_IOC, 0, 13)>,
				<HPMICRO_PINMUX(HPMICRO_PIN(HPMICRO_PORTE, 1), IOC_TYPE_IOC, 0, 13)>,
				<HPMICRO_PINMUX(HPMICRO_PIN(HPMICRO_PORTE, 2), IOC_TYPE_IOC, 0, 13)>,
				<HPMICRO_PINMUX(HPMICRO_PIN(HPMICRO_PORTE, 3), IOC_TYPE_IOC, 0, 13)>,
				<HPMICRO_PINMUX(HPMICRO_PIN(HPMICRO_PORTC, 29), IOC_TYPE_IOC, 0, 13)>;
		};
	};

	pinmux_sdm: pinmux_sdm {
		group0 {
			pinmux = <HPMICRO_PINMUX(HPMICRO_PIN(HPMICRO_PORTF, 17), IOC_TYPE_IOC, 0, 23)>,
				<HPMICRO_PINMUX(HPMICRO_PIN(HPMICRO_PORTF, 16), IOC_TYPE_IOC, 0, 23)>;
		};
	};

	pinmux_esc: pinmux_esc {
		group0 {
			pinmux = <HPMICRO_PINMUX(HPMICRO_PIN(HPMICRO_PORTA, 9), IOC_TYPE_IOC, 0, 11)>,
				<HPMICRO_PINMUX(HPMICRO_PIN(HPMICRO_PORTA, 30), IOC_TYPE_IOC, 0, 11)>,
				<HPMICRO_PINMUX(HPMICRO_PIN(HPMICRO_PORTA, 31), IOC_TYPE_IOC, 0, 11)>,
				<HPMICRO_PINMUX(HPMICRO_PIN(HPMICRO_PORTA, 10), IOC_TYPE_IOC, 0, 0)>,
				<HPMICRO_PINMUX(HPMICRO_PIN(HPMICRO_PORTA, 15), IOC_TYPE_IOC, 0, 11)>,
				<HPMICRO_PINMUX(HPMICRO_PIN(HPMICRO_PORTA, 11), IOC_TYPE_IOC, 0, 11)>,
				<HPMICRO_PINMUX(HPMICRO_PIN(HPMICRO_PORTE, 2), IOC_TYPE_IOC, 0, 11)>,
				<HPMICRO_PINMUX(HPMICRO_PIN(HPMICRO_PORTE, 3), IOC_TYPE_IOC, 0, 11)>,
				<HPMICRO_PINMUX(HPMICRO_PIN(HPMICRO_PORTA, 24), IOC_TYPE_IOC, 0, 11)>,
				<HPMICRO_PINMUX(HPMICRO_PIN(HPMICRO_PORTA, 29), IOC_TYPE_IOC, 0, 11)>,
				<HPMICRO_PINMUX(HPMICRO_PIN(HPMICRO_PORTA, 25), IOC_TYPE_IOC, 0, 11)>,
				<HPMICRO_PINMUX(HPMICRO_PIN(HPMICRO_PORTA, 26), IOC_TYPE_IOC, 0, 11)>,
				<HPMICRO_PINMUX(HPMICRO_PIN(HPMICRO_PORTA, 27), IOC_TYPE_IOC, 0, 11)>,
				<HPMICRO_PINMUX(HPMICRO_PIN(HPMICRO_PORTA, 28), IOC_TYPE_IOC, 0, 11)>,
				<HPMICRO_PINMUX(HPMICRO_PIN(HPMICRO_PORTA, 21), IOC_TYPE_IOC, 0, 11)>,
				<HPMICRO_PINMUX(HPMICRO_PIN(HPMICRO_PORTA, 16), IOC_TYPE_IOC, 0, 11)>,
				<HPMICRO_PINMUX(HPMICRO_PIN(HPMICRO_PORTA, 23), IOC_TYPE_IOC, 0, 11)>,
				<HPMICRO_PINMUX(HPMICRO_PIN(HPMICRO_PORTA, 17), IOC_TYPE_IOC, 0, 11)>,
				<HPMICRO_PINMUX(HPMICRO_PIN(HPMICRO_PORTA, 18), IOC_TYPE_IOC, 0, 11)>,
				<HPMICRO_PINMUX(HPMICRO_PIN(HPMICRO_PORTA, 19), IOC_TYPE_IOC, 0, 11)>,
				<HPMICRO_PINMUX(HPMICRO_PIN(HPMICRO_PORTA, 20), IOC_TYPE_IOC, 0, 11)>,
				<HPMICRO_PINMUX(HPMICRO_PIN(HPMICRO_PORTB, 18), IOC_TYPE_IOC, 0, 11)>,
				<HPMICRO_PINMUX(HPMICRO_PIN(HPMICRO_PORTB, 23), IOC_TYPE_IOC, 0, 11)>,
				<HPMICRO_PINMUX(HPMICRO_PIN(HPMICRO_PORTB, 19), IOC_TYPE_IOC, 0, 11)>,
				<HPMICRO_PINMUX(HPMICRO_PIN(HPMICRO_PORTB, 20), IOC_TYPE_IOC, 0, 11)>,
				<HPMICRO_PINMUX(HPMICRO_PIN(HPMICRO_PORTB, 21), IOC_TYPE_IOC, 0, 11)>,
				<HPMICRO_PINMUX(HPMICRO_PIN(HPMICRO_PORTB, 22), IOC_TYPE_IOC, 0, 11)>,
				<HPMICRO_PINMUX(HPMICRO_PIN(HPMICRO_PORTB, 17), IOC_TYPE_IOC, 0, 11)>,
				<HPMICRO_PINMUX(HPMICRO_PIN(HPMICRO_PORTB, 12), IOC_TYPE_IOC, 0, 11)>,
				<HPMICRO_PINMUX(HPMICRO_PIN(HPMICRO_PORTA, 22), IOC_TYPE_IOC, 0, 11)>,
				<HPMICRO_PINMUX(HPMICRO_PIN(HPMICRO_PORTB, 13), IOC_TYPE_IOC, 0, 11)>,
				<HPMICRO_PINMUX(HPMICRO_PIN(HPMICRO_PORTB, 14), IOC_TYPE_IOC, 0, 11)>,
				<HPMICRO_PINMUX(HPMICRO_PIN(HPMICRO_PORTB, 15), IOC_TYPE_IOC, 0, 11)>,
				<HPMICRO_PINMUX(HPMICRO_PIN(HPMICRO_PORTB, 16), IOC_TYPE_IOC, 0, 11)>,
				<HPMICRO_PINMUX(HPMICRO_PIN(HPMICRO_PORTE, 6), IOC_TYPE_IOC, 0, 27)>;
		};
	};

	pinmux_esc_eeprom: pinmux_esc_eeprom {
		group0 {
			pinmux = <HPMICRO_PINMUX(HPMICRO_PIN(HPMICRO_PORTA, 12), IOC_TYPE_IOC, 0, 11)>,
				<HPMICRO_PINMUX(HPMICRO_PIN(HPMICRO_PORTA, 13), IOC_TYPE_IOC, 0, 11)>;
		};
	};

	pinmux_esc_eeprom_as_i2c: pinmux_esc_eeprom_as_i2c {
		group0 {
			pinmux = <HPMICRO_PINMUX(HPMICRO_PIN(HPMICRO_PORTA, 12), IOC_TYPE_IOC, 0, 4)>,
				<HPMICRO_PINMUX(HPMICRO_PIN(HPMICRO_PORTA, 13), IOC_TYPE_IOC, 0, 4)>;
			drive-open-drain;
			input-enable;
		};
	};

	pinmux_esc_in_out: pinmux_esc_in_out {
		group0 {
			pinmux = <HPMICRO_PINMUX(HPMICRO_PIN(HPMICRO_PORTC, 31), IOC_TYPE_IOC, 0, 0)>,
				<HPMICRO_PINMUX(HPMICRO_PIN(HPMICRO_PORTD, 8), IOC_TYPE_IOC, 0, 0)>,
				<HPMICRO_PINMUX(HPMICRO_PIN(HPMICRO_PORTD, 9), IOC_TYPE_IOC, 0, 0)>,
				<HPMICRO_PINMUX(HPMICRO_PIN(HPMICRO_PORTE, 14), IOC_TYPE_IOC, 0, 0)>;
		};
	};

	pinmux_tamper: pinmux_tamper {
		group0 {
			pinmux = <HPMICRO_PINMUX(HPMICRO_PIN(HPMICRO_PORTZ, 4), IOC_TYPE_BIOC, 0, 2)>,
				<HPMICRO_PINMUX(HPMICRO_PIN(HPMICRO_PORTZ, 5), IOC_TYPE_BIOC, 0, 2)>,
				<HPMICRO_PINMUX(HPMICRO_PIN(HPMICRO_PORTZ, 3), IOC_TYPE_BIOC, 0, 2)>;
		};
	};

	pinmux_brownout_indicate: pinmux_brownout_indicate {
		group0 {
			pinmux = <HPMICRO_PINMUX(HPMICRO_PIN(HPMICRO_PORTY, 5), IOC_TYPE_IOC, 0, 0)>,
				<HPMICRO_PINMUX(HPMICRO_PIN(HPMICRO_PORTY, 5), IOC_TYPE_PIOC, 0, 3)>;
		};
	};

	pinmux_puart: pinmux_puart {
		group0 {
			pinmux = <HPMICRO_PINMUX(HPMICRO_PIN(HPMICRO_PORTY, 0), IOC_TYPE_PIOC, 0, 1)>,
				<HPMICRO_PINMUX(HPMICRO_PIN(HPMICRO_PORTY, 1), IOC_TYPE_PIOC, 0, 1)>;
		};
	};

	pinmux_sdram_card_detect: pinmux_sdram_card_detect {
		group0 {
			pinmux = <HPMICRO_PINMUX(HPMICRO_PIN(HPMICRO_PORTF, 14), IOC_TYPE_IOC, 0, 0)>;
		};
	};
};
